# HR_C7000_DM32 register map
Vendor: Dahua Technology (chip); Baofeng (radio product); Series: HR_C7000; File version: 0.1-dm32re-draft
CPU: other r0p0, little endian, no MPU, no FPU, 0 interrupt priority bits
Registers are 32-bit, read-write, reset 0x0 unless marked. A register's access mark holds for its fields unless they carry their own. Offsets are from the block's base; [hi:lo] are bit positions.

## WDG — Watchdog (DS §4.10, p.212-218). Write 0x5ada7200 to WDG_LOCK to unlock; feed by writing 0x55aadd22 to WDG_KNOCK; a timeout causes a full global reset (v2.2 manual p.32). Default timeout ~60 s, reset pulse ~20 ms. FW: base literal at 0x0305728c (no movih-built accesses). Neither magic value appears as a literal in program flash or the IRAM image, so whether and how stock feeds it is not established. QEMU: the dm32uv-qemu port maps it as plain RAM (it never bites).
Base 0x14010000
0x00 WDG_LOCK reset 0x1 — Watchdog Lock Register. DS §4.10.5.1 p.216. Reset 0x1 (DS).
  [31:0] WDG_LOCK — 0x5ada_7200 to this register will enable write access to all registers, and writing other values to this register will disable write access to all registers. Reading this register will return the locked status: 0x0 : write allowed, unlocked 0x1 : write disabled, locked [reset 0x1] [access RW]
0x04 WDG_OT_LOAD_H reset 0x7 — DS §4.10.5.2 p.216. Reset 0x7 (DS).
  [2:0] WDG_OT_LOAD_H — The high initial value of the timeout counter. When the high initial value of the timeout counter overflows, it indicates Timeout, the default timeout is about 60s [reset 0x7] [access RW]
0x08 WDG_OT_LOAD_L ro reset 0xC0000000 — DS §4.10.5.3 p.216. The datasheet marks WDG_OT_LOAD_L read-only while its high half (WDG_OT_LOAD_H) is read-write; possibly a datasheet error, not verified. Reset 0xc0000000 (DS).
  [31:0] WDG_OT_LOAD_L — The low initial value of the timeout counter, when the high counter overflows, Indicates timeout. The default timeout is about 60s . [reset 0xc0000000] [access RO]
0x0C WDG_RST_LOAD — Watchdog reset time initial value. DS §4.10.5.4 p.218.
  [24:0] WDG_RST_LOAD — The initial value of the watchdog reset time is reset after counting to 0x03ffffff Completed, the default reset time is about 20ms [reset 0x03f80000] [access RW]
0x10 WDG_EN — Watchdog enable. DS §4.10.5.5 p.218. Reset 0x0 (DS).
  [0] WDG_EN — Watchdog enable signal 0 : Watchdog is off and no watchdog reset is generated 1 : Watchdog is working. If the watchdog is not fed within the timeout period, a watchdog reset will occur. [reset 0x0] [access RW]
0x14 WDG_KNOCK — Watchdog feeding register. DS §4.10.5.6 p.218. Reset 0x0 (DS).
  [31:0] WDG_KNOCK — Feed the dog signal, write 0x55aadd22 to feed the dog, watchdog timeout The counter restarts counting. [reset 0x0] [access RW]

## GPIOA — GPIO bank A, Synopsys DesignWare APB GPIO (DS §5.7, p.377-385). Every register is one bit per pin. Pin functions are selected in SystemControl.IO_DIPLEX0-2 first. FW: 158 access sites. Note: decompiler output may show GPIO accesses as uRam00000000: the movih/bseti high-address idiom is not always constant-folded.
Base 0x14020000
Same registers: GPIOB 0x14100000, GPIOC 0x14110000
0x00 SWPORTA_DR — Port A output data. DS §5.7.5.1 p.381. FW: 16 reads, 11 writes. Reset 0x0 (DS).
0x04 SWPORTA_DDR — Control port A data direction. DS §5.7.5.2 p.381. FW: 22 reads, 19 writes. Reset 0x0 (DS).
0x30 INTEN — Interrupt enable. DS §5.7.5.3 p.383. FW: 10 reads, 10 writes. Reset 0x0 (DS).
0x34 INTMASK — Controls whether to mask interrupts. DS §5.7.5.4 p.383. FW: 3 reads, 3 writes. Reset 0x0 (DS).
0x38 INTTYPE_LEVEL — Controls the interrupt type of port A. DS §5.7.5.5 p.383. FW: 9 reads, 9 writes. Reset 0x0 (DS).
0x3C INT_POLARITY — Controls the polarity of the interrupt on port A. DS §5.7.5.6 p.383. FW: 11 reads, 11 writes. Reset 0x0 (DS).
0x40 INTSTATUS ro — Port A interrupt status. DS §5.7.5.7 p.383. FW: 2 reads, 0 writes. Reset 0x0 (DS).
0x44 RAW_INTSTATUS ro — port A before masking. DS §5.7.5.8 p.383. Reset 0x0 (DS).
0x48 DEBOUNCE — Debounce Enable Register. DS §5.7.5.9 p.385. FW: 0 reads, 2 writes. Printed RO; the stock firmware writes it (FW: GPIOA/B/C +0x48, 2 writes each). Reset 0x0 (DS).
0x4C PORTA_EOI wo — PORTA interrupt clear register. 0 : Do not clear interrupt; 1 : Clearing Break. DS §5.7.5.10 p.385. FW: 0 reads, 1 write. Printed RO; it is the interrupt clear (write 1 to clear) and the stock firmware writes it (FW: +0x4c). Reset 0x0 (DS).
0x50 EXT_PORTA ro — When port A is configured as input, read this register to read the input data. DS §5.7.5.11 p.385. FW: 7 reads, 0 writes. Reset 0x0 (DS).
0x78 INTR_BOTH_EDGE — 1 : Dual-edge triggered interrupt 0 : Non-double-edge triggered interrupt. DS §5.7.5.12 p.385. FW: 6 reads, 6 writes. Note: To configure dual-edge interrupts, first configure gpio_inttype_level to edge trigger, and then configure register 0x78 . When dual-edge interrupts are not used, write 0 to register 0x78 . Reset 0x0 (DS).

## DAC — CPU-side 12-bit DAC controller, three channels A-C (DS §5.10, p.423-426). Distinct from the baseband TX DAC (SystemControl.DAC_CONTROL). FW: 8 sites, writing PD_CTRL, PD_MODE_EN and all three data registers.
Base 0x140F0000
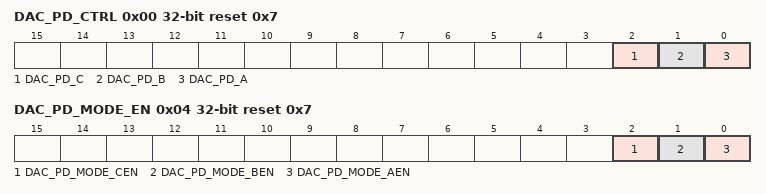
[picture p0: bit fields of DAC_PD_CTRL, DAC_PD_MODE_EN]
0x00 DAC_PD_CTRL reset 0x7 — DAC Enable. DS §5.10.5.1 p.423. FW: 0 reads, 1 write. Reset 0x7 (DS).
  [2] DAC_PD_C — DAC channel C power on and off control. 1 : Power off; 0 : Power on [reset 0x1] [access RW]
  [1] DAC_PD_B — DAC channel B power on and off control. 1 : Power off; 0 : Power on [reset 0x1] [access RW]
  [0] DAC_PD_A — DAC channel A power on and off control. 1 : Power off; 0 : Power on [reset 0x1] [access RW]
0x04 DAC_PD_MODE_EN reset 0x7 — DAC Low power enable. DS §5.10.5.2 p.423. FW: 0 reads, 1 write. Reset 0x7 (DS).
  [2] DAC_PD_MODE_CEN — DAC channel C low power mode enable. 1 : Enable; 0 : Shutdown [reset 0x1] [access RW]
  [1] DAC_PD_MODE_BEN — DAC channel B low power mode enable. 1 : Enable; 0 : Shutdown [reset 0x1] [access RW]
  [0] DAC_PD_MODE_AEN — DAC channel A low power mode enable. 1 : Enable; 0 : Disable Break [reset 0x1] [access RW]
0x08 DAC_DATA_A — DAC Channel A data. DS §5.10.5.3 p.425. FW: 0 reads, 2 writes. Reset 0x0 (DS).
  [11:0] DAC_DATA_A — DAC Channel A data [reset 0x0] [access RW]
0x0C DAC_DATA_B — DAC Channel B data. DS §5.10.5.4 p.425. FW: 0 reads, 2 writes. Reset 0x0 (DS).
  [11:0] DAC_DATA_B — DAC channel B data [reset 0x0] [access RW]
0x10 DAC_DATA_C — DAC Channel C data. DS §5.10.5.5 p.425. FW: 0 reads, 2 writes. Reset 0x0 (DS).
  [11:0] DAC_DATA_C — DAC Channel C data [reset 0x0] [access RW]
0x14 DAC_CTRL_VERID reset 0x20160229 — DAC Controller version. DS §5.10.5.6 p.425. Reset 0x20160229 (DS).
  [31:0] DAC_CTRL_VERID — Controller version number (for debugging only ) [reset 0x20160229] [access RW]
